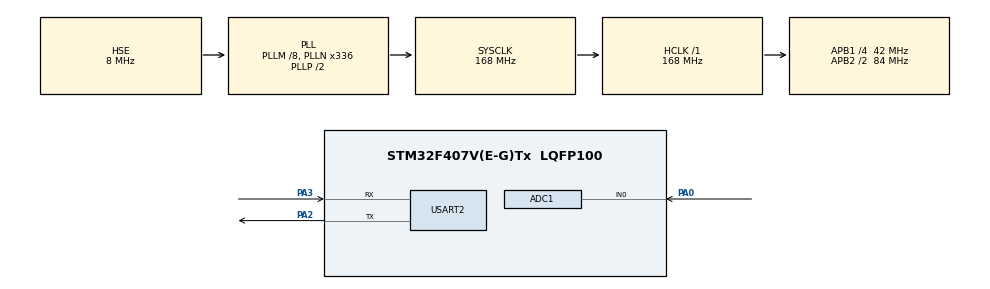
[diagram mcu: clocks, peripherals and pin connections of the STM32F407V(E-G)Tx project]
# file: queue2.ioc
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ADC1.Channel-0\#ChannelRegularConversion=ADC_CHANNEL_0
ADC1.NbrOfConversionFlag=1
ADC1.Rank-0\#ChannelRegularConversion=1
ADC1.SamplingTime-0\#ChannelRegularConversion=ADC_SAMPLETIME_3CYCLES
ADC1.master=1
FREERTOS.INCLUDE_vTaskDelayUntil=1
FREERTOS.Tasks01=defaultTask,-3,128,StartDefaultTask,Default,NULL,Dynamic,NULL,NULL
FREERTOS.configUSE_NEWLIB_REENTRANT=1
Mcu.Family=STM32F4
Mcu.Name=STM32F407V(E-G)Tx
Mcu.Package=LQFP100
NVIC.PriorityGroup=NVIC_PRIORITYGROUP_4
NVIC.TIM1_UP_TIM10_IRQn=true\:15\:0\:false\:false\:true\:false\:false\:true\:true
NVIC.TimeBase=TIM1_UP_TIM10_IRQn
NVIC.TimeBaseIP=TIM1
PA0-WKUP.Signal=ADCx_IN0
PA2.Mode=Asynchronous
PA2.Signal=USART2_TX
PA3.Mode=Asynchronous
PA3.Signal=USART2_RX
PH0-OSC_IN.Mode=HSE-External-Oscillator
PH0-OSC_IN.Signal=RCC_OSC_IN
PH1-OSC_OUT.Mode=HSE-External-Oscillator
PH1-OSC_OUT.Signal=RCC_OSC_OUT
ProjectManager.HeapSize=0x200
ProjectManager.StackSize=0x400
ProjectManager.TargetToolchain=STM32CubeIDE
RCC.48MHZClocksFreq_Value=48000000
RCC.AHBFreq_Value=168000000
RCC.APB1CLKDivider=RCC_HCLK_DIV4
RCC.APB1Freq_Value=42000000
RCC.APB1TimFreq_Value=84000000
RCC.APB2CLKDivider=RCC_HCLK_DIV2
RCC.APB2Freq_Value=84000000
RCC.APB2TimFreq_Value=168000000
RCC.CortexFreq_Value=168000000
RCC.HCLKFreq_Value=168000000
RCC.HSE_VALUE=8000000
RCC.HSI_VALUE=16000000
RCC.LSE_VALUE=32768
RCC.PLLM=8
RCC.PLLN=336
RCC.PLLQ=7
RCC.PLLSourceVirtual=RCC_PLLSOURCE_HSE
RCC.SYSCLKFreq_VALUE=168000000
RCC.SYSCLKSource=RCC_SYSCLKSOURCE_PLLCLK
RCC.VCOOutputFreq_Value=336000000
SH.ADCx_IN0.0=ADC1_IN0,IN0
USART2.VirtualMode=VM_ASYNC
VP_FREERTOS_VS_CMSIS_V1.Mode=CMSIS_V1
VP_SYS_VS_tim1.Mode=TIM1
board=STM32F407G-DISC1

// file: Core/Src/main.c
/* USER CODE BEGIN Header */
/**
  ******************************************************************************
  * @file           : main.c
  * @brief          : Main program body
  ******************************************************************************
  * @attention
  *
  * Copyright (c) 2024 STMicroelectronics.
  * All rights reserved.
  *
  * This software is licensed under terms that can be found in the LICENSE file
  * in the root directory of this software component.
  * If no LICENSE file comes with this software, it is provided AS-IS.
  *
  ******************************************************************************
  */
/* USER CODE END Header */
#include "main.h"
#include "cmsis_os.h"

/* USER CODE BEGIN Includes */
#include<string.h>
#include<stdio.h>
/* USER CODE END Includes */

ADC_HandleTypeDef hadc1;

UART_HandleTypeDef huart2;

osThreadId defaultTaskHandle;
/* USER CODE BEGIN PV */
xQueueHandle xQueue;
/* USER CODE END PV */

void SystemClock_Config(void);
static void MX_GPIO_Init(void);
static void MX_USART2_UART_Init(void);
static void MX_ADC1_Init(void);
void StartDefaultTask(void const * argument);

/* USER CODE BEGIN 0 */

void vSenderTask(void *pvParam)
{
	uint32_t adcVal;

	TickType_t xTickCount = xTaskGetTickCount();
	while(1){
		HAL_ADC_Start(&hadc1);
		HAL_ADC_PollForConversion(&hadc1, HAL_MAX_DELAY);
		adcVal = HAL_ADC_GetValue(&hadc1);
		HAL_ADC_Stop(&hadc1);
		xQueueSendToBack(xQueue, &adcVal, portMAX_DELAY);
		vTaskDelayUntil(&xTickCount, 3000 / portTICK_RATE_MS);
	}
	vTaskDelete(NULL);
}

void vReceiverTask(void *pvParam)
{
	uint32_t adcVal;
	char msg[20];

	while((xQueueReceive(xQueue, &adcVal, portMAX_DELAY)) == pdPASS)
	{
		portENTER_CRITICAL();
		uint32_t count = sprintf(msg, "ADC Value : %ld\r\n", adcVal);
		HAL_UART_Transmit(&huart2, (uint8_t *)msg, count, HAL_MAX_DELAY);
		portEXIT_CRITICAL();
	}
	vTaskDelete(NULL);
}
/* USER CODE END 0 */

int main(void)
{

  /* MCU Configuration--------------------------------------------------------*/

  /* Reset of all peripherals, Initializes the Flash interface and the Systick. */
  HAL_Init();

  /* Configure the system clock */
  SystemClock_Config();

  /* Initialize all configured peripherals */
  MX_GPIO_Init();
  MX_USART2_UART_Init();
  MX_ADC1_Init();

  /* USER CODE BEGIN RTOS_QUEUES */
  xQueue = xQueueCreate(5, 4);
  /* USER CODE END RTOS_QUEUES */

  /* Create the thread(s) */
  /* definition and creation of defaultTask */
  osThreadDef(defaultTask, StartDefaultTask, osPriorityIdle, 0, 128);
  defaultTaskHandle = osThreadCreate(osThread(defaultTask), NULL);

  /* USER CODE BEGIN RTOS_THREADS */
  xTaskCreate(vSenderTask, "Sender", 128, NULL, 5, NULL);
  xTaskCreate(vReceiverTask, "Receiver", 128, NULL, 4, NULL);
  /* USER CODE END RTOS_THREADS */

  /* Start scheduler */
  osKernelStart();

  /* We should never get here as control is now taken by the scheduler */
  /* Infinite loop */
  while (1)
  {

  }
}

void SystemClock_Config(void)
{
  RCC_OscInitTypeDef RCC_OscInitStruct = {0};
  RCC_ClkInitTypeDef RCC_ClkInitStruct = {0};

  /** Configure the main internal regulator output voltage
  */
  __HAL_RCC_PWR_CLK_ENABLE();
  __HAL_PWR_VOLTAGESCALING_CONFIG(PWR_REGULATOR_VOLTAGE_SCALE1);

  /** Initializes the RCC Oscillators according to the specified parameters
  * in the RCC_OscInitTypeDef structure.
  */
  RCC_OscInitStruct.OscillatorType = RCC_OSCILLATORTYPE_HSE;
  RCC_OscInitStruct.HSEState = RCC_HSE_ON;
  RCC_OscInitStruct.PLL.PLLState = RCC_PLL_ON;
  RCC_OscInitStruct.PLL.PLLSource = RCC_PLLSOURCE_HSE;
  RCC_OscInitStruct.PLL.PLLM = 8;
  RCC_OscInitStruct.PLL.PLLN = 336;
  RCC_OscInitStruct.PLL.PLLP = RCC_PLLP_DIV2;
  RCC_OscInitStruct.PLL.PLLQ = 7;
  if (HAL_RCC_OscConfig(&RCC_OscInitStruct) != HAL_OK)
  {
    Error_Handler();
  }

  /** Initializes the CPU, AHB and APB buses clocks
  */
  RCC_ClkInitStruct.ClockType = RCC_CLOCKTYPE_HCLK|RCC_CLOCKTYPE_SYSCLK
                              |RCC_CLOCKTYPE_PCLK1|RCC_CLOCKTYPE_PCLK2;
  RCC_ClkInitStruct.SYSCLKSource = RCC_SYSCLKSOURCE_PLLCLK;
  RCC_ClkInitStruct.AHBCLKDivider = RCC_SYSCLK_DIV1;
  RCC_ClkInitStruct.APB1CLKDivider = RCC_HCLK_DIV4;
  RCC_ClkInitStruct.APB2CLKDivider = RCC_HCLK_DIV2;

  if (HAL_RCC_ClockConfig(&RCC_ClkInitStruct, FLASH_LATENCY_5) != HAL_OK)
  {
    Error_Handler();
  }
}

static void MX_ADC1_Init(void)
{

  ADC_ChannelConfTypeDef sConfig = {0};

  /** Configure the global features of the ADC (Clock, Resolution, Data Alignment and number of conversion)
  */
  hadc1.Instance = ADC1;
  hadc1.Init.ClockPrescaler = ADC_CLOCK_SYNC_PCLK_DIV4;
  hadc1.Init.Resolution = ADC_RESOLUTION_12B;
  hadc1.Init.ScanConvMode = DISABLE;
  hadc1.Init.ContinuousConvMode = DISABLE;
  hadc1.Init.DiscontinuousConvMode = DISABLE;
  hadc1.Init.ExternalTrigConvEdge = ADC_EXTERNALTRIGCONVEDGE_NONE;
  hadc1.Init.ExternalTrigConv = ADC_SOFTWARE_START;
  hadc1.Init.DataAlign = ADC_DATAALIGN_RIGHT;
  hadc1.Init.NbrOfConversion = 1;
  hadc1.Init.DMAContinuousRequests = DISABLE;
  hadc1.Init.EOCSelection = ADC_EOC_SINGLE_CONV;
  if (HAL_ADC_Init(&hadc1) != HAL_OK)
  {
    Error_Handler();
  }

  /** Configure for the selected ADC regular channel its corresponding rank in the sequencer and its sample time.
  */
  sConfig.Channel = ADC_CHANNEL_0;
  sConfig.Rank = 1;
  sConfig.SamplingTime = ADC_SAMPLETIME_3CYCLES;
  if (HAL_ADC_ConfigChannel(&hadc1, &sConfig) != HAL_OK)
  {
    Error_Handler();
  }

}

static void MX_USART2_UART_Init(void)
{

  huart2.Instance = USART2;
  huart2.Init.BaudRate = 115200;
  huart2.Init.WordLength = UART_WORDLENGTH_8B;
  huart2.Init.StopBits = UART_STOPBITS_1;
  huart2.Init.Parity = UART_PARITY_NONE;
  huart2.Init.Mode = UART_MODE_TX_RX;
  huart2.Init.HwFlowCtl = UART_HWCONTROL_NONE;
  huart2.Init.OverSampling = UART_OVERSAMPLING_16;
  if (HAL_UART_Init(&huart2) != HAL_OK)
  {
    Error_Handler();
  }

}

static void MX_GPIO_Init(void)
{

  /* GPIO Ports Clock Enable */
  __HAL_RCC_GPIOH_CLK_ENABLE();
  __HAL_RCC_GPIOA_CLK_ENABLE();

}

void StartDefaultTask(void const * argument)
{
  for(;;)
  {
    osDelay(1);
  }
}

void HAL_TIM_PeriodElapsedCallback(TIM_HandleTypeDef *htim)
{
  if (htim->Instance == TIM1) {
    HAL_IncTick();
  }
}

void Error_Handler(void)
{
  __disable_irq();
  while (1)
  {
  }
}
